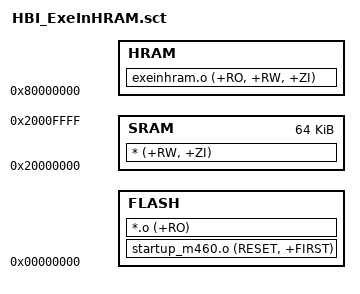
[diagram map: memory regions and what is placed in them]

LOAD_ROM  0x0
{
	FLASH  +0
	{
		startup_m460.o (RESET, +FIRST)
		*.o (+RO)
	}

	SRAM  0x20000000 0x10000
	{
		* (+RW, +ZI)
	}

    ; HyperRAM code
    HRAM  0x80000000
    {
        exeinhram.o (+RO, +RW, +ZI)
    }

}
